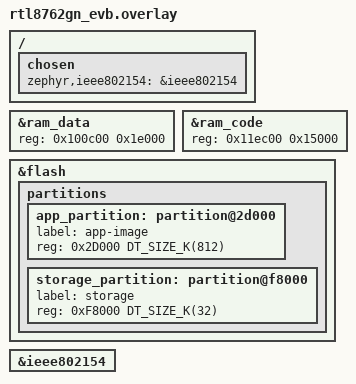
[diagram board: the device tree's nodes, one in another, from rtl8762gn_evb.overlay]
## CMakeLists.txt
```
cmake_minimum_required(VERSION 3.20.0)

find_package(Zephyr REQUIRED HINTS $ENV{ZEPHYR_BASE})

project(openthread_cli)

# NORDIC SDK APP START
target_sources(app PRIVATE
    src/main.c
    src/cts.c
)
target_link_options(app
    PUBLIC
        -Wl,--wrap,mac_EnterCritical_rom
        -Wl,--wrap,mac_ExitCritical_rom
        -Wl,--wrap,mac_RstRF_rom
        -Wl,--wrap,otPlatReset
)
```

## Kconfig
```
menu "Zephyr Kernel"
source "Kconfig.zephyr"
endmenu

module = OT_COMMAND_LINE_INTERFACE
module-str = ot_cli
source "${ZEPHYR_BASE}/subsys/logging/Kconfig.template.log_config"
```

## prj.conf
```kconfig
CONFIG_LOG=y
CONFIG_MAIN_STACK_SIZE=2048

# driver
CONFIG_REALTEK_MAC_802154=y

# Network shell
CONFIG_SHELL=y
CONFIG_OPENTHREAD_SHELL=y
CONFIG_SHELL_ARGC_MAX=26
CONFIG_SHELL_CMD_BUFF_SIZE=416

# Enable OpenThread features set
CONFIG_OPENTHREAD_THREAD_VERSION_1_3=y
CONFIG_OPENTHREAD_COAP=y
CONFIG_OPENTHREAD_COAPS=y
CONFIG_OPENTHREAD_COMMISSIONER=y
CONFIG_OPENTHREAD_DIAG=y
CONFIG_OPENTHREAD_DNS_CLIENT=y
CONFIG_OPENTHREAD_DHCP6_SERVER=y
CONFIG_OPENTHREAD_DHCP6_CLIENT=y
CONFIG_OPENTHREAD_ECDSA=y
CONFIG_OPENTHREAD_ENABLE_SERVICE=y
CONFIG_OPENTHREAD_EXTERNAL_HEAP=y
CONFIG_OPENTHREAD_IP6_FRAGM=y
CONFIG_OPENTHREAD_JAM_DETECTION=y
CONFIG_OPENTHREAD_JOINER=y
CONFIG_OPENTHREAD_MAC_FILTER=y
CONFIG_OPENTHREAD_NETDIAG_CLIENT=y
CONFIG_OPENTHREAD_RAW=y
CONFIG_OPENTHREAD_SLAAC=y
CONFIG_OPENTHREAD_SNTP_CLIENT=y
CONFIG_OPENTHREAD_SRP_CLIENT=y
CONFIG_OPENTHREAD_UDP_FORWARD=y
CONFIG_OPENTHREAD_DUA=y
CONFIG_OPENTHREAD_MLR=y
CONFIG_OPENTHREAD_LINK_METRICS_INITIATOR=y
CONFIG_OPENTHREAD_LINK_METRICS_SUBJECT=y
CONFIG_OPENTHREAD_CSL_RECEIVER=y

# Openthread L2
CONFIG_OPENTHREAD_MANUAL_START=y
CONFIG_NET_L2_OPENTHREAD=y

# Generic networking options
CONFIG_NETWORKING=y
CONFIG_NET_PKT_TXTIME=y
CONFIG_NET_PKT_TIMESTAMP=y

#CONFIG_MBEDTLS_SHA1_C=n
CONFIG_FPU=y

CONFIG_GPIO_SHELL=y

CONFIG_BT=y
CONFIG_LOG=y
CONFIG_BT_SMP=y
CONFIG_BT_SIGNING=y
CONFIG_BT_PERIPHERAL=y
CONFIG_BT_DIS=y
CONFIG_BT_ATT_PREPARE_COUNT=5
CONFIG_BT_BAS=y
CONFIG_BT_HRS=y
CONFIG_BT_IAS=y
CONFIG_BT_PRIVACY=y
CONFIG_BT_DEVICE_NAME="Zephyr Peripheral Sample Long Name"
CONFIG_BT_DEVICE_APPEARANCE=833
CONFIG_BT_DEVICE_NAME_DYNAMIC=y
CONFIG_BT_DEVICE_NAME_MAX=65

CONFIG_BT_KEYS_OVERWRITE_OLDEST=y
CONFIG_BT_SETTINGS=y
CONFIG_FLASH=y
CONFIG_FLASH_PAGE_LAYOUT=y
CONFIG_FLASH_MAP=y
CONFIG_NVS=y
CONFIG_SETTINGS=y
```

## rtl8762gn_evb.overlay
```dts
/* Copyright (c) 2020 Nordic Semiconductor ASA
 *
 * SPDX-License-Identifier: LicenseRef-Nordic-5-Clause
 */

&ram_data {
	reg = <0x100c00 0x1e000>;
};

&ram_code {
	reg = <0x11ec00 0x15000>;
};

&flash {
	partitions {
		/delete-node/ partition@2d000;
		/delete-node/ partition@fc000;

		app_partition: partition@2d000 {
			label = "app-image";
			reg = <0x2D000 DT_SIZE_K(812)>;
		};
		storage_partition: partition@f8000 {
			label = "storage";
			reg = <0xF8000 DT_SIZE_K(32)>;
		};
	};
};

&ieee802154 {
	status = "okay";
};

/ {
	chosen {
		zephyr,ieee802154 = &ieee802154;
	};
};
```

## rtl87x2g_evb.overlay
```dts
/*
 * Copyright (c) 2024 Realtek Semiconductor Corp.
 *
 * SPDX-License-Identifier: Apache-2.0
 */

&flash {
	partitions {
		/delete-node/ partition@2d000;
		/delete-node/ partition@fc000;

		app_partition: partition@2d000 {
			label = "app-image";
			reg = <0x2D000 DT_SIZE_K(812)>;
		};
		storage_partition: partition@f8000 {
			label = "storage";
			reg = <0xF8000 DT_SIZE_K(32)>;
		};
	};
};

&ieee802154 {
	status = "okay";
};

/ {
	chosen {
		zephyr,ieee802154 = &ieee802154;
	};
};
```

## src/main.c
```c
/*
 * Copyright (c) 2024 Realtek Semiconductor Corp.
 *
 * SPDX-License-Identifier: Apache-2.0
 */
#include <zephyr/kernel.h>
#include <zephyr/shell/shell.h>
#include <version.h>
#include <zephyr/logging/log.h>
#include <stdlib.h>
#include <zephyr/drivers/uart.h>
#include <zephyr/usb/usb_device.h>
#include <ctype.h>

#ifdef CONFIG_ARCH_POSIX
#include <unistd.h>
#else
#include <zephyr/posix/unistd.h>
#endif

LOG_MODULE_REGISTER(app);

#include <openthread/instance.h>
#include <openthread/platform/time.h>
#include <openthread/platform/alarm-milli.h>
#include <openthread/platform/alarm-micro.h>
#include <openthread-system.h>
#include <trace.h>

// replace misc.c
extern void WDG_SystemReset(int wdt_mode, int reset_reason);
void __wrap_otPlatReset(otInstance *aInstance)
{
 	ARG_UNUSED(aInstance);
	WDG_SystemReset(0, 0xff);
}

int main(void)
{
#if DT_NODE_HAS_COMPAT(DT_CHOSEN(zephyr_shell_uart), zephyr_cdc_acm_uart)
	const struct device *dev;
	uint32_t dtr = 0;

	dev = DEVICE_DT_GET(DT_CHOSEN(zephyr_shell_uart));
	if (!device_is_ready(dev) || usb_enable(NULL)) {
		return 0;
	}

	while (!dtr) {
		uart_line_ctrl_get(dev, UART_LINE_CTRL_DTR, &dtr);
		k_sleep(K_MSEC(100));
	}
#endif
	return 0;
}
```
